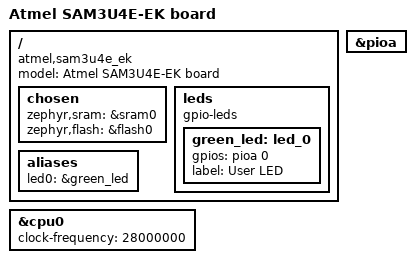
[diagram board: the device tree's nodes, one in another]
/*
 * Copyright (c) 2026
 * SPDX-License-Identifier: Apache-2.0
 */

/dts-v1/;

#include <arm/armv7-m.dtsi>
#include <zephyr/dt-bindings/gpio/gpio.h>
#include <atmel/sam3u4e.dtsi>

/ {
	model = "Atmel SAM3U4E-EK board";
	compatible = "atmel,sam3u4e_ek", "atmel,sam3u4e", "atmel,sam3u";

	chosen {
		zephyr,sram = &sram0;
		zephyr,flash = &flash0;
	};

	leds: leds {
		compatible = "gpio-leds";

		green_led: led_0 {
			gpios = <&pioa 0 GPIO_ACTIVE_HIGH>;
			label = "User LED";
		};
	};

	aliases {
		led0 = &green_led;
	};
};

&cpu0 {
	clock-frequency = <28000000>;
};

&pioa {
	status = "okay";
};
